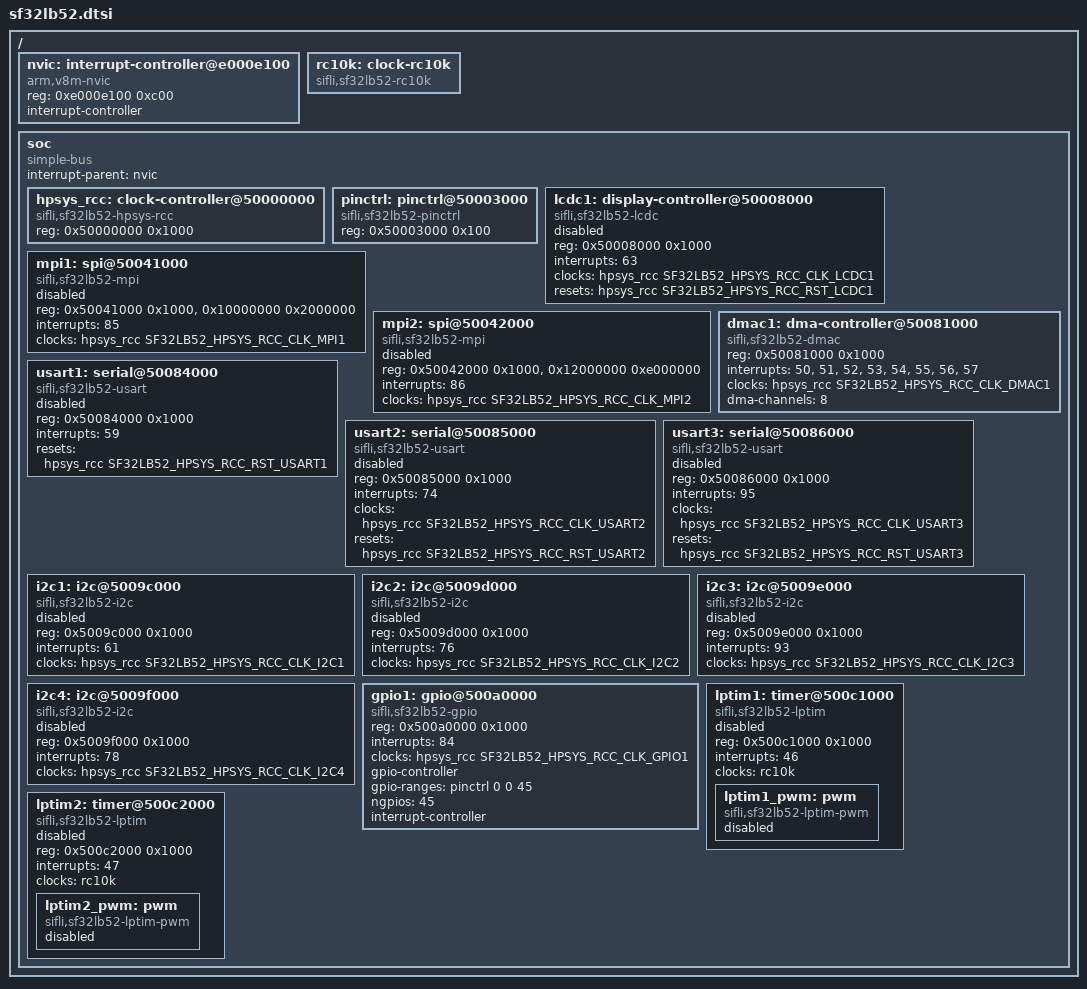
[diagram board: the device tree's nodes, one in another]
// SPDX-FileCopyrightText: 2026 Core Devices LLC
// SPDX-License-Identifier: (GPL-2.0-only OR BSD-2-Clause)

#include <dt-bindings/clock/sifli,sf32lb52-hpsys-rcc.h>
#include <dt-bindings/interrupt-controller/irq.h>
#include <dt-bindings/reset/sifli,sf32lb52-hpsys-rcc.h>

/ {
	#address-cells = <1>;
	#size-cells = <1>;

	nvic: interrupt-controller@e000e100 {
		compatible = "arm,v8m-nvic";
		reg = <0xe000e100 0xc00>;
		interrupt-controller;
		#interrupt-cells = <1>;
		#address-cells = <0>;
	};

	rc10k: clock-rc10k {
		compatible = "sifli,sf32lb52-rc10k";
		#clock-cells = <0>;
	};

	soc {
		compatible = "simple-bus";
		#address-cells = <1>;
		#size-cells = <1>;
		interrupt-parent = <&nvic>;
		ranges;

		hpsys_rcc: clock-controller@50000000 {
			compatible = "sifli,sf32lb52-hpsys-rcc";
			reg = <0x50000000 0x1000>;
			#clock-cells = <1>;
			#reset-cells = <1>;
		};

		pinctrl: pinctrl@50003000 {
			compatible = "sifli,sf32lb52-pinctrl";
			reg = <0x50003000 0x100>;
		};

		lcdc1: display-controller@50008000 {
			compatible = "sifli,sf32lb52-lcdc";
			reg = <0x50008000 0x1000>;
			interrupts = <63>;
			clocks = <&hpsys_rcc SF32LB52_HPSYS_RCC_CLK_LCDC1>;
			resets = <&hpsys_rcc SF32LB52_HPSYS_RCC_RST_LCDC1>;
			status = "disabled";
		};

		mpi1: spi@50041000 {
			compatible = "sifli,sf32lb52-mpi";
			reg = <0x50041000 0x1000>, <0x10000000 0x2000000>;
			reg-names = "mpi", "mpi_mm";
			interrupts = <85>;
			clocks = <&hpsys_rcc SF32LB52_HPSYS_RCC_CLK_MPI1>;
			#address-cells = <1>;
			#size-cells = <0>;
			status = "disabled";
		};

		mpi2: spi@50042000 {
			compatible = "sifli,sf32lb52-mpi";
			reg = <0x50042000 0x1000>, <0x12000000 0xe000000>;
			reg-names = "mpi", "mpi_mm";
			interrupts = <86>;
			clocks = <&hpsys_rcc SF32LB52_HPSYS_RCC_CLK_MPI2>;
			#address-cells = <1>;
			#size-cells = <0>;
			status = "disabled";
		};

		dmac1: dma-controller@50081000 {
			compatible = "sifli,sf32lb52-dmac";
			reg = <0x50081000 0x1000>;
			interrupts = <50>, <51>, <52>, <53>, <54>, <55>, <56>, <57>;
			clocks = <&hpsys_rcc SF32LB52_HPSYS_RCC_CLK_DMAC1>;
			#dma-cells = <3>;
			dma-channels = <8>;
		};

		usart1: serial@50084000 {
			compatible = "sifli,sf32lb52-usart";
			reg = <0x50084000 0x1000>;
			interrupts = <59>;
			resets = <&hpsys_rcc SF32LB52_HPSYS_RCC_RST_USART1>;
			status = "disabled";
		};

		usart2: serial@50085000 {
			compatible = "sifli,sf32lb52-usart";
			reg = <0x50085000 0x1000>;
			interrupts = <74>;
			clocks = <&hpsys_rcc SF32LB52_HPSYS_RCC_CLK_USART2>;
			resets = <&hpsys_rcc SF32LB52_HPSYS_RCC_RST_USART2>;
			status = "disabled";
		};

		usart3: serial@50086000 {
			compatible = "sifli,sf32lb52-usart";
			reg = <0x50086000 0x1000>;
			interrupts = <95>;
			clocks = <&hpsys_rcc SF32LB52_HPSYS_RCC_CLK_USART3>;
			resets = <&hpsys_rcc SF32LB52_HPSYS_RCC_RST_USART3>;
			status = "disabled";
		};

		i2c1: i2c@5009c000 {
			compatible = "sifli,sf32lb52-i2c";
			reg = <0x5009c000 0x1000>;
			interrupts = <61>;
			clocks = <&hpsys_rcc SF32LB52_HPSYS_RCC_CLK_I2C1>;
			#address-cells = <1>;
			#size-cells = <0>;
			status = "disabled";
		};

		i2c2: i2c@5009d000 {
			compatible = "sifli,sf32lb52-i2c";
			reg = <0x5009d000 0x1000>;
			interrupts = <76>;
			clocks = <&hpsys_rcc SF32LB52_HPSYS_RCC_CLK_I2C2>;
			#address-cells = <1>;
			#size-cells = <0>;
			status = "disabled";
		};

		i2c3: i2c@5009e000 {
			compatible = "sifli,sf32lb52-i2c";
			reg = <0x5009e000 0x1000>;
			interrupts = <93>;
			clocks = <&hpsys_rcc SF32LB52_HPSYS_RCC_CLK_I2C3>;
			#address-cells = <1>;
			#size-cells = <0>;
			status = "disabled";
		};

		i2c4: i2c@5009f000 {
			compatible = "sifli,sf32lb52-i2c";
			reg = <0x5009f000 0x1000>;
			interrupts = <78>;
			clocks = <&hpsys_rcc SF32LB52_HPSYS_RCC_CLK_I2C4>;
			#address-cells = <1>;
			#size-cells = <0>;
			status = "disabled";
		};

		gpio1: gpio@500a0000 {
			compatible = "sifli,sf32lb52-gpio";
			reg = <0x500a0000 0x1000>;
			interrupts = <84>;
			clocks = <&hpsys_rcc SF32LB52_HPSYS_RCC_CLK_GPIO1>;
			gpio-controller;
			gpio-ranges = <&pinctrl 0 0 45>;
			#gpio-cells = <2>;
			ngpios = <45>;
			interrupt-controller;
			#interrupt-cells = <2>;
		};

		lptim1: timer@500c1000 {
			compatible = "sifli,sf32lb52-lptim";
			reg = <0x500c1000 0x1000>;
			interrupts = <46>;
			clocks = <&rc10k>;
			status = "disabled";

			lptim1_pwm: pwm {
				compatible = "sifli,sf32lb52-lptim-pwm";
				#pwm-cells = <3>;
				status = "disabled";
			};
		};

		lptim2: timer@500c2000 {
			compatible = "sifli,sf32lb52-lptim";
			reg = <0x500c2000 0x1000>;
			interrupts = <47>;
			clocks = <&rc10k>;
			status = "disabled";

			lptim2_pwm: pwm {
				compatible = "sifli,sf32lb52-lptim-pwm";
				#pwm-cells = <3>;
				status = "disabled";
			};
		};
	};
};
